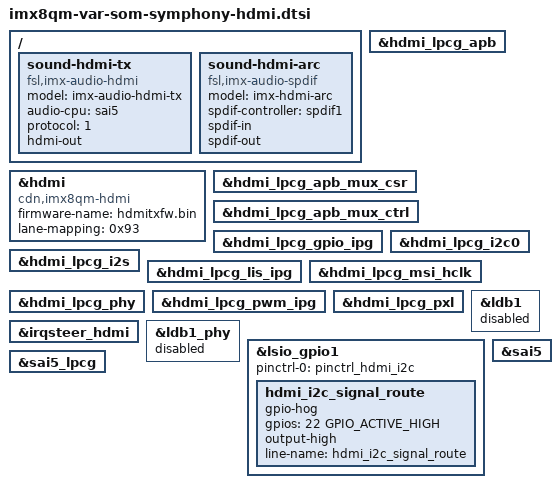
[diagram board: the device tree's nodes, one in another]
/*
 * Copyright 2019-2022 Variscite Ltd.
 *
 * This program is free software; you can redistribute it and/or
 * modify it under the terms of the GNU General Public License
 * as published by the Free Software Foundation; either version 2
 * of the License, or (at your option) any later version.
 *
 * This program is distributed in the hope that it will be useful,
 * but WITHOUT ANY WARRANTY; without even the implied warranty of
 * MERCHANTABILITY or FITNESS FOR A PARTICULAR PURPOSE.  See the
 * GNU General Public License for more details.
 */

#include "imx8qm-var-som-symphony.dtsi"

/ {
	sound-hdmi-tx {
		compatible = "fsl,imx-audio-hdmi";
		model = "imx-audio-hdmi-tx";
		audio-cpu = <&sai5>;
		protocol = <1>;
		hdmi-out;
	};

	sound-hdmi-arc {
		compatible = "fsl,imx-audio-spdif";
		model = "imx-hdmi-arc";
		spdif-controller = <&spdif1>;
		spdif-in;
		spdif-out;
	};
};

&hdmi {
	compatible = "cdn,imx8qm-hdmi";
	firmware-name = "hdmitxfw.bin";
	lane-mapping = <0x93>;
	status = "okay";
};

&hdmi_lpcg_apb {
	status = "okay";
};

&hdmi_lpcg_apb_mux_csr {
	status = "okay";
};

&hdmi_lpcg_apb_mux_ctrl {
	status = "okay";
};

&hdmi_lpcg_gpio_ipg {
	status = "okay";
};

&hdmi_lpcg_i2c0 {
	status = "okay";
};

&hdmi_lpcg_i2s {
	status = "okay";
};

&hdmi_lpcg_lis_ipg {
	status = "okay";
};

&hdmi_lpcg_msi_hclk {
	status = "okay";
};

&hdmi_lpcg_phy {
	status = "okay";
};

&hdmi_lpcg_pwm_ipg {
	status = "okay";
};

&hdmi_lpcg_pxl {
	status = "okay";
};

&irqsteer_hdmi {
	status = "okay";
};

&ldb1 {
	status = "disabled";
};

&ldb1_phy {
	status = "disabled";
};

&lsio_gpio1 {
        pinctrl-names = "default";
        pinctrl-0 = <&pinctrl_hdmi_i2c>;

        hdmi_i2c_signal_route {
                gpio-hog;
                gpios = <22 GPIO_ACTIVE_HIGH>;
                output-high;
                line-name = "hdmi_i2c_signal_route";
        };
};

&sai5 {
	status = "okay";
};

&sai5_lpcg {
	status = "okay";
};
